# PY32F002Bxx register map
Vendor: Puya; Series: PY32F0; File version: 1.0.0
CPU: CM0+ r0p1, little endian, no MPU, no FPU, 4 interrupt priority bits
Registers are 32-bit, read-write, reset 0x0 unless marked. A register's access mark holds for its fields unless they carry their own. Offsets are from the block's base; [hi:lo] are bit positions; {n}, {i} and the like mark numbered series.

## COMP1 — Comparator 1
Base 0x40010200
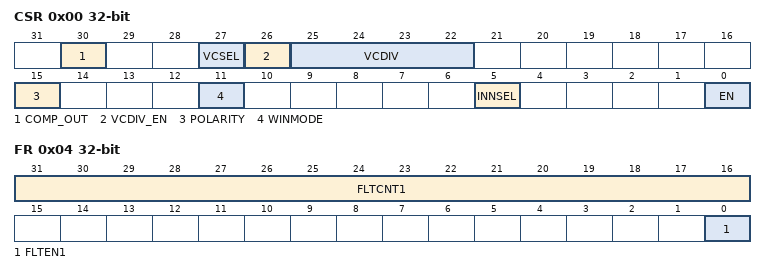
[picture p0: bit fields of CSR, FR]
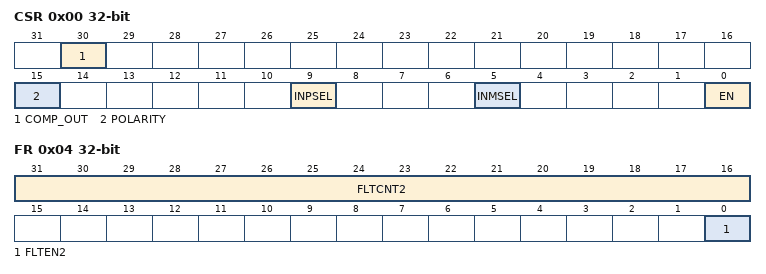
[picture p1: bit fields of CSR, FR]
0x00 CSR — COMP control and status register
  [30] COMP_OUT — Comparator output status
  [27] VCSEL
  [26] VCDIV_EN
  [25:22] VCDIV
  [15] POLARITY — Comparator polarity selector
  [11] WINMODE — Comparator non-inverting input selector for window mode
  [5] INNSEL
  [0] EN — COMP enable bit
0x04 FR — Comparator Filter register
  [31:16] FLTCNT1 — Comparator filter and counter
  [0] FLTEN1 — Filter enable bit

## COMP2 — Comparator2
Base 0x40010210
0x00 CSR — COMP control and status register
  [30] COMP_OUT — Comparator output status
  [15] POLARITY — Comparator polarity selector
  [9] INPSEL — Comparator signal selector for non-inverting input
  [5] INMSEL — Comparator signal selector for inverting input INM
  [0] EN — COMP enable bit
0x04 FR — Comparator Filter register
  [31:16] FLTCNT2 — Comparator filter and counter
  [0] FLTEN2 — Filter enable bit

## CRC — CRC calculation unit
Base 0x40023000
0x00 DR reset 0xFFFFFFFF — Data register
  [31:0] DR — Data Register
0x04 IDR — Independent Data register
  [7:0] IDR
0x08 CR wo — Control register
  [0] RESET — Reset bit

## DBGMCU — Debug support
Base 0x40015800
0x00 IDCODE ro — MCU Device ID Code Register
  [31:0] REV_ID
0x04 CR — Debug MCU Configuration Register
  [1] DBG_STOP — Debug Stop Mode
0x08 APB_FZ1 — APB Freeze Register1
  [31] DBG_LPTIM_STOP — Debug LPTIM stopped when Core ishalted
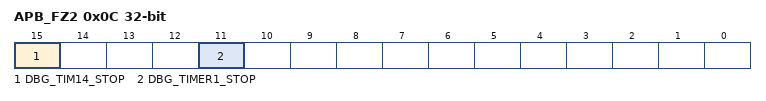
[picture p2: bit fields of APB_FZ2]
0x0C APB_FZ2 — APB Freeze Register2
  [15] DBG_TIM14_STOP — Debug TIM 14 stopped whenCore is halted
  [11] DBG_TIMER1_STOP — Debug Timer 1 stopped when Core ishalted

## EXTI — External interrupt/event controller
Base 0x40021800
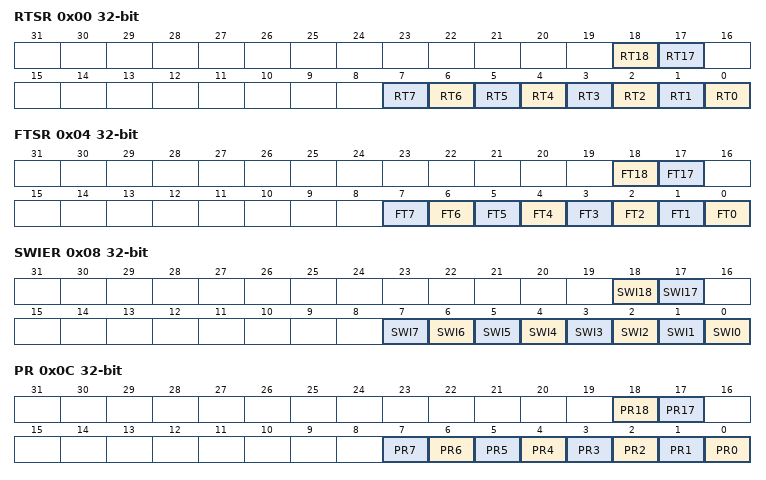
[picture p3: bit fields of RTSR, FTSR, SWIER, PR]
0x00 RTSR — EXTI rising trigger selection register
  [18] RT18 — Rising trigger event configuration bit of Configurable Event input
  [17] RT17 — Rising trigger event configuration bit of Configurable Event input
  [n] RT{n} (n=0..7) — Rising trigger event configuration bit of Configurable Event input
0x04 FTSR — EXTI falling trigger selection register
  [18] FT18 — Falling trigger event configuration bit of Configurable Event input
  [17] FT17 — Falling trigger event configuration bit of Configurable Event input
  [n] FT{n} (n=0..7) — Falling trigger event configuration bit of Configurable Event input
0x08 SWIER — EXTI software interrupt event register
  [18] SWI18 — Rising trigger event configuration bit of Configurable Event input
  [17] SWI17 — Rising trigger event configuration bit of Configurable Event input
  [n] SWI{n} (n=0..7) — Rising trigger event configuration bit of Configurable Event input
0x0C PR — EXTI pending register
  [18] PR18 — configurable event inputs x rising edge Pending bit.
  [17] PR17 — configurable event inputs x rising edge Pending bit.
  [n] PR{n} (n=0..7) — configurable event inputs x rising edge Pending bit.
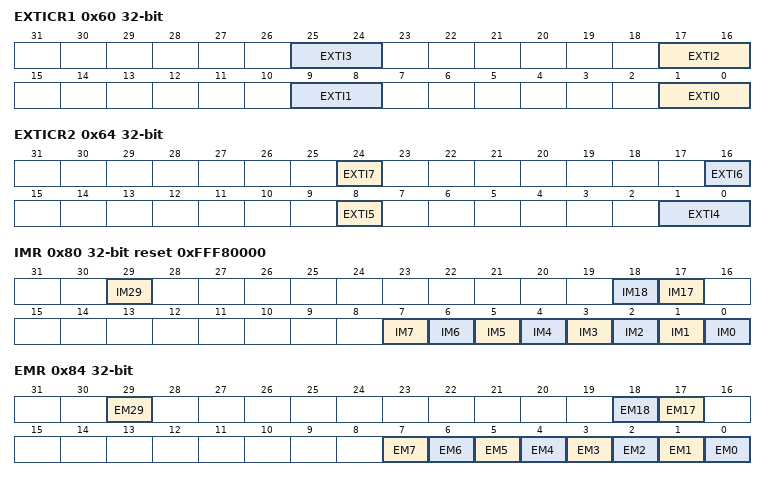
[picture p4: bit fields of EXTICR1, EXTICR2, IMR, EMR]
0x60 EXTICR1 — EXTI external interrupt selection register
  [all] fields
    1=0; 2=1
  [8n+1:8n] EXTI{n} (n=0..3) — GPIO port selection
0x64 EXTICR2 — EXTI external interrupt selection register
  [24] EXTI7 — GPIO port selection
  [16] EXTI6 — GPIO port selection
  [8] EXTI5 — GPIO port selection
  [1:0] EXTI4 — GPIO port selection
    1=0; 2=1
0x80 IMR reset 0xFFF80000 — EXTI CPU wakeup with interrupt mask register
  [29] IM29 — CPU wakeup with interrupt mask on event input
  [18] IM18 — CPU wakeup with interrupt mask on event input
  [17] IM17 — CPU wakeup with interrupt mask on event input
  [n] IM{n} (n=0..7) — CPU wakeup with interrupt mask on event input
0x84 EMR — EXTI CPU wakeup with event mask register
  [29] EM29 — CPU wakeup with event mask on event input
  [18] EM18 — CPU wakeup with event mask on event input
  [17] EM17 — CPU wakeup with event mask on event input
  [n] EM{n} (n=0..7) — CPU wakeup with event mask on event input
